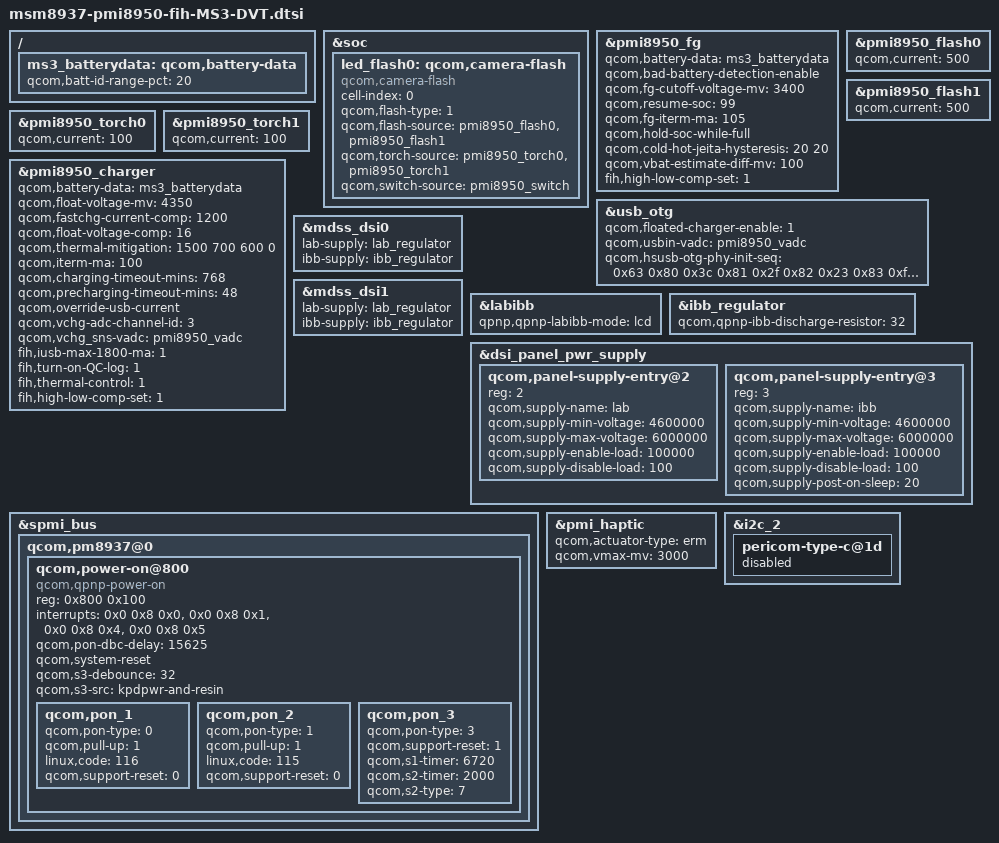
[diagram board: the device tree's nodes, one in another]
/*
 * Copyright (c) 2015-2016, The Linux Foundation. All rights reserved.
 *
 * This program is free software; you can redistribute it and/or modify
 * it under the terms of the GNU General Public License version 2 and
 * only version 2 as published by the Free Software Foundation.
 *
 * This program is distributed in the hope that it will be useful,
 * but WITHOUT ANY WARRANTY; without even the implied warranty of
 * MERCHANTABILITY or FITNESS FOR A PARTICULAR PURPOSE.  See the
 * GNU General Public License for more details.
 */

#include "msm-pmi8950.dtsi"
#include "msm8937-fih-MS3-v0.dtsi"
#include "msm8937-audio-mtp.dtsi"

&soc {
	led_flash0: qcom,camera-flash {
		cell-index = <0>;
		compatible = "qcom,camera-flash";
		qcom,flash-type = <1>;
		qcom,flash-source = <&pmi8950_flash0 &pmi8950_flash1>;
		qcom,torch-source = <&pmi8950_torch0 &pmi8950_torch1>;
		qcom,switch-source = <&pmi8950_switch>;
	};
};

/{
	ms3_batterydata: qcom,battery-data {
		qcom,batt-id-range-pct = <20>;
		#include "components/power/batterydata-MS3.dtsi"
		#include "components/power/batterydata-MS3_2530.dtsi"
	};
};

&pmi8950_fg {
	qcom,battery-data = <&ms3_batterydata>;
	qcom,bad-battery-detection-enable;
	qcom,fg-cutoff-voltage-mv = <3400>;
	qcom,resume-soc = <99>;
	qcom,fg-iterm-ma = <105>;
	qcom,hold-soc-while-full;
	qcom,cold-hot-jeita-hysteresis = <20 20>;
	qcom,vbat-estimate-diff-mv = <100>;
	fih,high-low-comp-set = <1>;
};

&pmi8950_flash0 {
       qcom,current = <500>;
};

&pmi8950_flash1 {
       qcom,current = <500>;
};

&pmi8950_torch0 {
       qcom,current = <100>;
};

&pmi8950_torch1 {
       qcom,current = <100>;
};

&pmi8950_charger {
	status = "ok";
	qcom,battery-data = <&ms3_batterydata>;
//	qcom,chg-led-sw-controls;
//	qcom,chg-led-support;
	qcom,float-voltage-mv = <4350>;
	qcom,fastchg-current-comp = <1200>;
	qcom,float-voltage-comp = <16>; /* need change to 16 if float-voltage change to 4.4 */
	qcom,thermal-mitigation = <1500 700 600 0>;
	qcom,iterm-ma = <100>;
	qcom,charging-timeout-mins = <768>;
	qcom,precharging-timeout-mins = <48>;
	qcom,override-usb-current;
	qcom,vchg-adc-channel-id = <3>;
	qcom,vchg_sns-vadc = <&pmi8950_vadc>;
	fih,iusb-max-1800-ma = <1>;
	fih,turn-on-QC-log = <1>;
	fih,thermal-control = <1>;
	fih,high-low-comp-set = <1>;
};

&usb_otg {
	qcom,floated-charger-enable = <1>;
	qcom,usbin-vadc = <&pmi8950_vadc>;
	//Fihtdc@peter, adjust usb init seq. for eye diagram
	qcom,hsusb-otg-phy-init-seq =
		<0x63 0x80 0x3c 0x81 0x2f 0x82 0x23 0x83 0xffffffff>;
};

&mdss_dsi0 {
	lab-supply = <&lab_regulator>;
	ibb-supply = <&ibb_regulator>;
};

&mdss_dsi1 {
	lab-supply = <&lab_regulator>;
	ibb-supply = <&ibb_regulator>;
};

&labibb {
	status = "ok";
	qpnp,qpnp-labibb-mode = "lcd";
};

&ibb_regulator {
	qcom,qpnp-ibb-discharge-resistor = <32>;
};

&dsi_panel_pwr_supply {
	qcom,panel-supply-entry@2 {
		reg = <2>;
		qcom,supply-name = "lab";
		qcom,supply-min-voltage = <4600000>;
		qcom,supply-max-voltage = <6000000>;
		qcom,supply-enable-load = <100000>;
		qcom,supply-disable-load = <100>;
	};

	qcom,panel-supply-entry@3 {
		reg = <3>;
		qcom,supply-name = "ibb";
		qcom,supply-min-voltage = <4600000>;
		qcom,supply-max-voltage = <6000000>;
		qcom,supply-enable-load = <100000>;
		qcom,supply-disable-load = <100>;
		qcom,supply-post-on-sleep = <20>;
	};
};

&spmi_bus {

/*
  AlanHZChang, Follow FIH BOOT REQE V3.0,
   - PMIC RESIN: Volume UP KEY(KEY CODE 115)
   - KPDPWR/RESIN DO NOT TRIGGER RESET FUNCTION
   - KPDPWR+RESIN TRIGGER RESET FUNCTION
*/
  qcom,pm8937@0 {
		qcom,power-on@800 {
			compatible = "qcom,qpnp-power-on";
			reg = <0x800 0x100>;
			interrupts = <0x0 0x8 0x0>,
				<0x0 0x8 0x1>,
				<0x0 0x8 0x4>,
				<0x0 0x8 0x5>;
			interrupt-names = "kpdpwr", "resin",
				"resin-bark", "kpdpwr-resin-bark";
			qcom,pon-dbc-delay = <15625>;
			qcom,system-reset;
			qcom,s3-debounce = <32>;
			qcom,s3-src = "kpdpwr-and-resin";

			/* PON: KPDPWR */
			qcom,pon_1 {
				qcom,pon-type = <0>;
				qcom,pull-up = <1>;
				linux,code = <116>;
				qcom,support-reset = <0>;
			};

			/* PON: RESIN */
			qcom,pon_2 {
				qcom,pon-type = <1>;
				qcom,pull-up = <1>;
				linux,code = <115>;
				qcom,support-reset = <0>;
			};

      /* PON: KPDPWR + RESIN */
			qcom,pon_3 {
				qcom,pon-type = <3>;
				qcom,support-reset = <1>;
				/* RESET TRIGGER TIME: S1 + S2 = 8720ms */
				qcom,s1-timer = <6720>;
				qcom,s2-timer = <2000>;
				qcom,s2-type = <7>;
			};
		};
	};
};

&pmi_haptic{
       qcom,actuator-type = "erm";
       qcom,vmax-mv = <3000>;
};

&i2c_2 {
	pericom-type-c@1d {
		status="disabled";
	};
};
